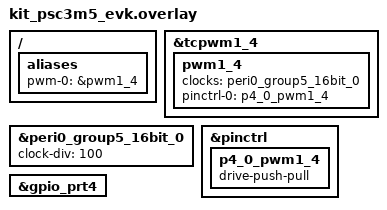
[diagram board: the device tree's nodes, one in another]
/*
 * SPDX-FileCopyrightText: Copyright (c) 2026 Infineon Technologies AG,
 * SPDX-FileCopyrightText: or an affiliate of Infineon Technologies AG. All rights reserved.
 *
 * SPDX-License-Identifier: Apache-2.0
 */

/ {
	aliases {
		pwm-0 = &pwm1_4;
	};
};

&tcpwm1_4 {
	status = "okay";

	pwm1_4: pwm1_4 {
		clocks = <&peri0_group5_16bit_0>;
		pinctrl-0 = <&p4_0_pwm1_4>;
		pinctrl-names = "default";
		status = "okay";
	};
};

&peri0_group5_16bit_0 {
	clock-div = <100>;
	status = "okay";
};

&pinctrl {
	p4_0_pwm1_4: p4_0_pwm1_4 {
		drive-push-pull;
	};
};

&gpio_prt4 {
	status = "okay";
};
